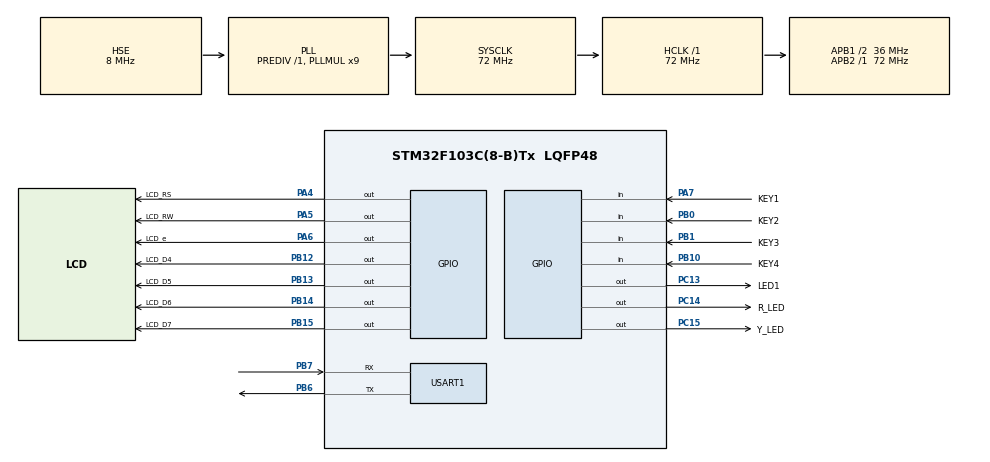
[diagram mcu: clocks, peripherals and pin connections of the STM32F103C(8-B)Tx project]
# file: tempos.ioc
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Mcu.Family=STM32F1
Mcu.Name=STM32F103C(8-B)Tx
Mcu.Package=LQFP48
NVIC.PriorityGroup=NVIC_PRIORITYGROUP_4
PA13.Mode=Serial_Wire
PA13.Signal=SYS_JTMS-SWDIO
PA14.Mode=Serial_Wire
PA14.Signal=SYS_JTCK-SWCLK
PA4.GPIO_Label=LCD_RS
PA4.GPIO_Speed=GPIO_SPEED_FREQ_HIGH
PA4.Signal=GPIO_Output
PA5.GPIO_Label=LCD_RW
PA5.GPIO_Speed=GPIO_SPEED_FREQ_HIGH
PA5.Signal=GPIO_Output
PA6.GPIO_Label=LCD_e
PA6.GPIO_ModeDefaultOutputPP=GPIO_MODE_OUTPUT_PP
PA6.GPIO_PuPd=GPIO_NOPULL
PA6.GPIO_Speed=GPIO_SPEED_FREQ_HIGH
PA6.Signal=GPIO_Output
PA7.GPIO_Label=KEY1
PA7.GPIO_PuPd=GPIO_PULLUP
PA7.Signal=GPIO_Input
PB0.GPIO_Label=KEY2
PB0.GPIO_PuPd=GPIO_PULLUP
PB0.Signal=GPIO_Input
PB1.GPIO_Label=KEY3
PB1.GPIO_PuPd=GPIO_PULLUP
PB1.Signal=GPIO_Input
PB10.GPIO_Label=KEY4
PB10.GPIO_PuPd=GPIO_PULLUP
PB10.Signal=GPIO_Input
PB12.GPIO_Label=LCD_D4
PB12.GPIO_Speed=GPIO_SPEED_FREQ_HIGH
PB12.Signal=GPIO_Output
PB13.GPIO_Label=LCD_D5
PB13.GPIO_Speed=GPIO_SPEED_FREQ_HIGH
PB13.Signal=GPIO_Output
PB14.GPIO_Label=LCD_D6
PB14.GPIO_Speed=GPIO_SPEED_FREQ_HIGH
PB14.Signal=GPIO_Output
PB15.GPIO_Label=LCD_D7
PB15.GPIO_Speed=GPIO_SPEED_FREQ_HIGH
PB15.Signal=GPIO_Output
PB6.Mode=Asynchronous
PB6.Signal=USART1_TX
PB7.Mode=Asynchronous
PB7.Signal=USART1_RX
PC13-TAMPER-RTC.GPIO_Label=LED1
PC13-TAMPER-RTC.Signal=GPIO_Output
PC14-OSC32_IN.GPIO_Label=R_LED
PC14-OSC32_IN.GPIO_PuPd=GPIO_NOPULL
PC14-OSC32_IN.GPIO_Speed=GPIO_SPEED_FREQ_MEDIUM
PC14-OSC32_IN.Signal=GPIO_Output
PC15-OSC32_OUT.GPIO_Label=Y_LED
PC15-OSC32_OUT.GPIO_PuPd=GPIO_NOPULL
PC15-OSC32_OUT.GPIO_Speed=GPIO_SPEED_FREQ_MEDIUM
PC15-OSC32_OUT.Signal=GPIO_Output
PD0-OSC_IN.Mode=HSE-External-Oscillator
PD0-OSC_IN.Signal=RCC_OSC_IN
PD1-OSC_OUT.Mode=HSE-External-Oscillator
PD1-OSC_OUT.Signal=RCC_OSC_OUT
ProjectManager.HeapSize=0x200
ProjectManager.StackSize=0x400
ProjectManager.TargetToolchain=STM32CubeIDE
RCC.AHBFreq_Value=72000000
RCC.APB1CLKDivider=RCC_HCLK_DIV2
RCC.APB1Freq_Value=36000000
RCC.APB1TimFreq_Value=72000000
RCC.APB2Freq_Value=72000000
RCC.APB2TimFreq_Value=72000000
RCC.HCLKFreq_Value=72000000
RCC.PLLMUL=RCC_PLL_MUL9
RCC.PLLSourceVirtual=RCC_PLLSOURCE_HSE
RCC.SYSCLKFreq_VALUE=72000000
RCC.SYSCLKSource=RCC_SYSCLKSOURCE_PLLCLK
RCC.USBFreq_Value=72000000
USART1.VirtualMode=VM_ASYNC
USART1.WordLength=WORDLENGTH_8B
board=custom

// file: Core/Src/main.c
/* USER CODE BEGIN Header */
/**
  ******************************************************************************
  * @file           : main.c
  * @brief          : Main program body
  ******************************************************************************
  * @attention
  *
  * Copyright (c) 2022 STMicroelectronics.
  * All rights reserved.
  *
  * This software is licensed under terms that can be found in the LICENSE file
  * in the root directory of this software component.
  * If no LICENSE file comes with this software, it is provided AS-IS.
  *
  ******************************************************************************
  */
/* USER CODE END Header */
#include "main.h"
#include "lcd.h"

UART_HandleTypeDef huart1;

void SystemClock_Config(void);
static void MX_GPIO_Init(void);
static void MX_USART1_UART_Init(void);

int main(void)
{

  /* MCU Configuration--------------------------------------------------------*/

  /* Reset of all peripherals, Initializes the Flash interface and the Systick. */
  HAL_Init();

  /* Configure the system clock */
  SystemClock_Config();

  /* Initialize all configured peripherals */
  MX_GPIO_Init();
  MX_USART1_UART_Init();
  /* USER CODE BEGIN 2 */

  uint8_t STRING[]  = "Pratica de Controle Digital!\r\n";
  HAL_GPIO_WritePin(GPIOC, R_LED_Pin, GPIO_PIN_RESET);
  HAL_GPIO_WritePin(GPIOC, Y_LED_Pin, GPIO_PIN_RESET);
  //float atraso = 0.0;

  /* USER CODE END 2 */

  /* Infinite loop */
  while (1)
  {
	  HAL_GPIO_WritePin(GPIOC, R_LED_Pin, GPIO_PIN_SET);
	  HAL_UART_Transmit(&huart1, STRING,sizeof(STRING),1000);
	  HAL_GPIO_WritePin(GPIOC, R_LED_Pin, GPIO_PIN_RESET);
	  HAL_GPIO_WritePin(GPIOC, Y_LED_Pin, GPIO_PIN_SET);
	  HAL_Delay(5);
	  HAL_GPIO_WritePin(GPIOC, Y_LED_Pin, GPIO_PIN_RESET);

  }
}

void SystemClock_Config(void)
{
  RCC_OscInitTypeDef RCC_OscInitStruct = {0};
  RCC_ClkInitTypeDef RCC_ClkInitStruct = {0};

  /** Initializes the RCC Oscillators according to the specified parameters
  * in the RCC_OscInitTypeDef structure.
  */
  RCC_OscInitStruct.OscillatorType = RCC_OSCILLATORTYPE_HSE;
  RCC_OscInitStruct.HSEState = RCC_HSE_ON;
  RCC_OscInitStruct.HSEPredivValue = RCC_HSE_PREDIV_DIV1;
  RCC_OscInitStruct.HSIState = RCC_HSI_ON;
  RCC_OscInitStruct.PLL.PLLState = RCC_PLL_ON;
  RCC_OscInitStruct.PLL.PLLSource = RCC_PLLSOURCE_HSE;
  RCC_OscInitStruct.PLL.PLLMUL = RCC_PLL_MUL9;
  if (HAL_RCC_OscConfig(&RCC_OscInitStruct) != HAL_OK)
  {
    Error_Handler();
  }

  /** Initializes the CPU, AHB and APB buses clocks
  */
  RCC_ClkInitStruct.ClockType = RCC_CLOCKTYPE_HCLK|RCC_CLOCKTYPE_SYSCLK
                              |RCC_CLOCKTYPE_PCLK1|RCC_CLOCKTYPE_PCLK2;
  RCC_ClkInitStruct.SYSCLKSource = RCC_SYSCLKSOURCE_PLLCLK;
  RCC_ClkInitStruct.AHBCLKDivider = RCC_SYSCLK_DIV1;
  RCC_ClkInitStruct.APB1CLKDivider = RCC_HCLK_DIV2;
  RCC_ClkInitStruct.APB2CLKDivider = RCC_HCLK_DIV1;

  if (HAL_RCC_ClockConfig(&RCC_ClkInitStruct, FLASH_LATENCY_2) != HAL_OK)
  {
    Error_Handler();
  }
}

static void MX_USART1_UART_Init(void)
{

  huart1.Instance = USART1;
  huart1.Init.BaudRate = 9600;
  huart1.Init.WordLength = UART_WORDLENGTH_8B;
  huart1.Init.StopBits = UART_STOPBITS_1;
  huart1.Init.Parity = UART_PARITY_NONE;
  huart1.Init.Mode = UART_MODE_TX_RX;
  huart1.Init.HwFlowCtl = UART_HWCONTROL_NONE;
  huart1.Init.OverSampling = UART_OVERSAMPLING_16;
  if (HAL_UART_Init(&huart1) != HAL_OK)
  {
    Error_Handler();
  }

}

static void MX_GPIO_Init(void)
{
  GPIO_InitTypeDef GPIO_InitStruct = {0};

  /* GPIO Ports Clock Enable */
  __HAL_RCC_GPIOC_CLK_ENABLE();
  __HAL_RCC_GPIOD_CLK_ENABLE();
  __HAL_RCC_GPIOA_CLK_ENABLE();
  __HAL_RCC_GPIOB_CLK_ENABLE();

  /*Configure GPIO pin Output Level */
  HAL_GPIO_WritePin(GPIOC, LED1_Pin|R_LED_Pin|Y_LED_Pin, GPIO_PIN_RESET);

  /*Configure GPIO pin Output Level */
  HAL_GPIO_WritePin(GPIOA, LCD_RS_Pin|LCD_RW_Pin|LCD_e_Pin, GPIO_PIN_RESET);

  /*Configure GPIO pin Output Level */
  HAL_GPIO_WritePin(GPIOB, LCD_D4_Pin|LCD_D5_Pin|LCD_D6_Pin|LCD_D7_Pin, GPIO_PIN_RESET);

  /*Configure GPIO pin : LED1_Pin */
  GPIO_InitStruct.Pin = LED1_Pin;
  GPIO_InitStruct.Mode = GPIO_MODE_OUTPUT_PP;
  GPIO_InitStruct.Pull = GPIO_NOPULL;
  GPIO_InitStruct.Speed = GPIO_SPEED_FREQ_LOW;
  HAL_GPIO_Init(LED1_GPIO_Port, &GPIO_InitStruct);

  /*Configure GPIO pins : R_LED_Pin Y_LED_Pin */
  GPIO_InitStruct.Pin = R_LED_Pin|Y_LED_Pin;
  GPIO_InitStruct.Mode = GPIO_MODE_OUTPUT_PP;
  GPIO_InitStruct.Pull = GPIO_NOPULL;
  GPIO_InitStruct.Speed = GPIO_SPEED_FREQ_MEDIUM;
  HAL_GPIO_Init(GPIOC, &GPIO_InitStruct);

  /*Configure GPIO pins : LCD_RS_Pin LCD_RW_Pin LCD_e_Pin */
  GPIO_InitStruct.Pin = LCD_RS_Pin|LCD_RW_Pin|LCD_e_Pin;
  GPIO_InitStruct.Mode = GPIO_MODE_OUTPUT_PP;
  GPIO_InitStruct.Pull = GPIO_NOPULL;
  GPIO_InitStruct.Speed = GPIO_SPEED_FREQ_HIGH;
  HAL_GPIO_Init(GPIOA, &GPIO_InitStruct);

  /*Configure GPIO pin : KEY1_Pin */
  GPIO_InitStruct.Pin = KEY1_Pin;
  GPIO_InitStruct.Mode = GPIO_MODE_INPUT;
  GPIO_InitStruct.Pull = GPIO_PULLUP;
  HAL_GPIO_Init(KEY1_GPIO_Port, &GPIO_InitStruct);

  /*Configure GPIO pins : KEY2_Pin KEY3_Pin KEY4_Pin */
  GPIO_InitStruct.Pin = KEY2_Pin|KEY3_Pin|KEY4_Pin;
  GPIO_InitStruct.Mode = GPIO_MODE_INPUT;
  GPIO_InitStruct.Pull = GPIO_PULLUP;
  HAL_GPIO_Init(GPIOB, &GPIO_InitStruct);

  /*Configure GPIO pins : LCD_D4_Pin LCD_D5_Pin LCD_D6_Pin LCD_D7_Pin */
  GPIO_InitStruct.Pin = LCD_D4_Pin|LCD_D5_Pin|LCD_D6_Pin|LCD_D7_Pin;
  GPIO_InitStruct.Mode = GPIO_MODE_OUTPUT_PP;
  GPIO_InitStruct.Pull = GPIO_NOPULL;
  GPIO_InitStruct.Speed = GPIO_SPEED_FREQ_HIGH;
  HAL_GPIO_Init(GPIOB, &GPIO_InitStruct);

}

void Error_Handler(void)
{
  __disable_irq();
  while (1)
  {
  }
}
